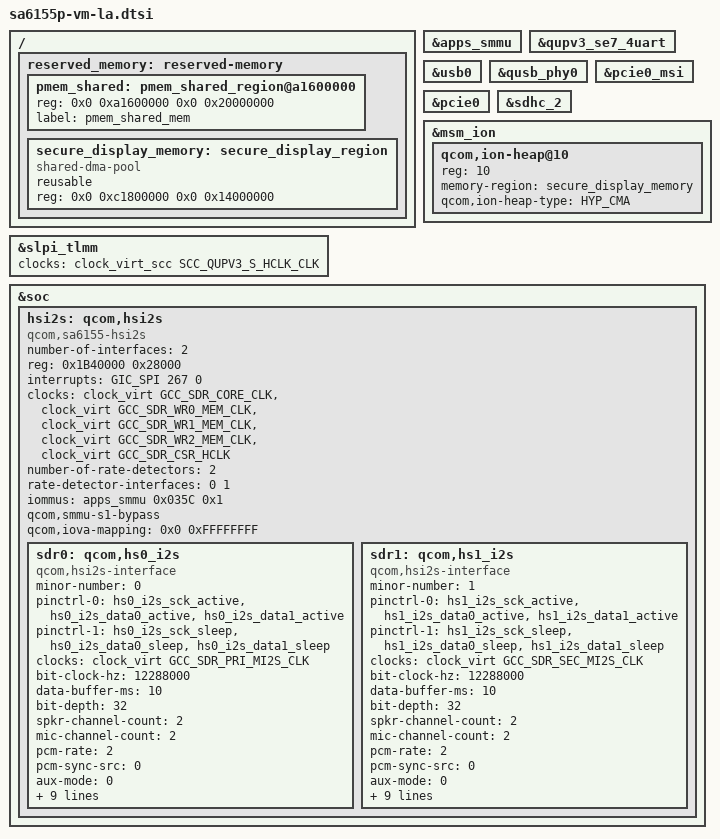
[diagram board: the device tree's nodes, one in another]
/*
 * Copyright (c) 2019-2020, The Linux Foundation. All rights reserved.

 * This program is free software; you can redistribute it and/or modify
 * it under the terms of the GNU General Public License version 2 and
 * only version 2 as published by the Free Software Foundation.

 * This program is distributed in the hope that it will be useful,
 * but WITHOUT ANY WARRANTY; without even the implied warranty of
 * MERCHANTABILITY or FITNESS FOR A PARTICULAR PURPOSE.  See the
 * GNU General Public License for more details.
 */


#include "sa6155p-vm.dtsi"

/ {
	reserved_memory: reserved-memory {

		pmem_shared: pmem_shared_region@a1600000 {
			reg = <0x0 0xa1600000 0x0 0x20000000>;
			label = "pmem_shared_mem";
		};

		secure_display_memory: secure_display_region {
			compatible = "shared-dma-pool";
			reusable;
			reg = <0x0 0xc1800000 0x0 0x14000000>;
		};
	};
};

&slpi_tlmm {
	clocks =  <&clock_virt_scc SCC_QUPV3_S_HCLK_CLK>;
	status = "ok";
};

&apps_smmu {
	status = "ok";
};

&qupv3_se7_4uart {
	status = "ok";
};

&usb0 {
	status = "ok";
};

&qusb_phy0 {
	status = "ok";
};

&pcie0_msi {
	status = "ok";
};

&pcie0 {
	status = "ok";
};

&sdhc_2 {
	status = "ok";
};

&msm_ion {
	qcom,ion-heap@10 {
		reg = <10>;
		memory-region = <&secure_display_memory>;
		qcom,ion-heap-type = "HYP_CMA";
	};
};

&soc {
	hsi2s: qcom,hsi2s {
		compatible = "qcom,sa6155-hsi2s", "qcom,hsi2s";
		number-of-interfaces = <2>;
		reg = <0x1B40000 0x28000>;
		reg-names = "lpa_if";
		interrupts = <GIC_SPI 267 0>;
		clocks = <&clock_virt GCC_SDR_CORE_CLK>,
			 <&clock_virt GCC_SDR_WR0_MEM_CLK>,
			 <&clock_virt GCC_SDR_WR1_MEM_CLK>,
			 <&clock_virt GCC_SDR_WR2_MEM_CLK>,
			 <&clock_virt GCC_SDR_CSR_HCLK>;
		clock-names = "core_clk", "wr0_mem_clk",
			      "wr1_mem_clk", "wr2_mem_clk",
			      "csr_hclk";
		number-of-rate-detectors = <2>;
		rate-detector-interfaces = <0 1>;
		iommus = <&apps_smmu 0x035C 0x1>;
		qcom,smmu-s1-bypass;
		qcom,iova-mapping = <0x0 0xFFFFFFFF>;

		sdr0: qcom,hs0_i2s {
			compatible = "qcom,hsi2s-interface";
			minor-number = <0>;
			pinctrl-names = "default", "sleep";
			pinctrl-0 = <&hs0_i2s_sck_active &hs0_i2s_data0_active
				     &hs0_i2s_data1_active>;
			pinctrl-1 = <&hs0_i2s_sck_sleep &hs0_i2s_data0_sleep
				     &hs0_i2s_data1_sleep>;
			clocks = <&clock_virt GCC_SDR_PRI_MI2S_CLK>;
			clock-names = "pri_mi2s_clk";
			bit-clock-hz = <12288000>;
			data-buffer-ms = <10>;
			bit-depth = <32>;
			spkr-channel-count = <2>;
			mic-channel-count = <2>;
			pcm-rate = <2>;
			pcm-sync-src = <0>;
			aux-mode = <0>;
			rpcm-width = <1>;
			tpcm-width = <1>;
			enable-tdm = <1>;
			tdm-rate = <32>;
			tdm-rpcm-width = <16>;
			tdm-tpcm-width = <16>;
			tdm-sync-delay = <2>;
			tdm-inv-sync = <0>;
			pcm-lane-config = <1>;
		};

		sdr1: qcom,hs1_i2s {
			compatible = "qcom,hsi2s-interface";
			minor-number = <1>;
			pinctrl-names = "default", "sleep";
			pinctrl-0 = <&hs1_i2s_sck_active &hs1_i2s_data0_active
				     &hs1_i2s_data1_active>;
			pinctrl-1 = <&hs1_i2s_sck_sleep &hs1_i2s_data0_sleep
				     &hs1_i2s_data1_sleep>;
			clocks = <&clock_virt GCC_SDR_SEC_MI2S_CLK>;
			clock-names = "sec_mi2s_clk";
			bit-clock-hz = <12288000>;
			data-buffer-ms = <10>;
			bit-depth = <32>;
			spkr-channel-count = <2>;
			mic-channel-count = <2>;
			pcm-rate = <2>;
			pcm-sync-src = <0>;
			aux-mode = <0>;
			rpcm-width = <1>;
			tpcm-width = <1>;
			enable-tdm = <1>;
			tdm-rate = <32>;
			tdm-rpcm-width = <16>;
			tdm-tpcm-width = <16>;
			tdm-sync-delay = <2>;
			tdm-inv-sync = <0>;
			pcm-lane-config = <1>;
		};
	};
};
